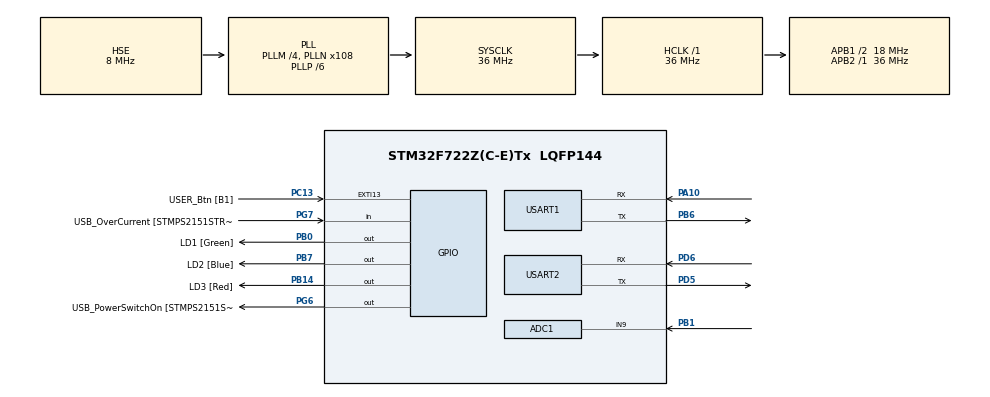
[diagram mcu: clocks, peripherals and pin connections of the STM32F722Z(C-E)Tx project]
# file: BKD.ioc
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ADC1.Channel-0\#ChannelRegularConversion=ADC_CHANNEL_9
ADC1.ClockPrescaler=ADC_CLOCK_SYNC_PCLK_DIV8
ADC1.ContinuousConvMode=ENABLE
ADC1.DMAContinuousRequests=ENABLE
ADC1.NbrOfConversionFlag=1
ADC1.Rank-0\#ChannelRegularConversion=1
ADC1.SamplingTime-0\#ChannelRegularConversion=ADC_SAMPLETIME_480CYCLES
ADC1.master=1
Dma.ADC1.0.Direction=DMA_PERIPH_TO_MEMORY
Dma.ADC1.0.FIFOMode=DMA_FIFOMODE_DISABLE
Dma.ADC1.0.Instance=DMA2_Stream0
Dma.ADC1.0.MemDataAlignment=DMA_MDATAALIGN_HALFWORD
Dma.ADC1.0.MemInc=DMA_MINC_ENABLE
Dma.ADC1.0.Mode=DMA_NORMAL
Dma.ADC1.0.PeriphDataAlignment=DMA_PDATAALIGN_HALFWORD
Dma.ADC1.0.PeriphInc=DMA_PINC_DISABLE
Dma.ADC1.0.Priority=DMA_PRIORITY_MEDIUM
Dma.Request0=ADC1
Mcu.Family=STM32F7
Mcu.Name=STM32F722Z(C-E)Tx
Mcu.Package=LQFP144
NVIC.ADC_IRQn=true\:0\:0\:false\:false\:true\:true\:true
NVIC.DMA2_Stream0_IRQn=true\:0\:0\:false\:false\:true\:false\:true
NVIC.PriorityGroup=NVIC_PRIORITYGROUP_4
NVIC.USART1_IRQn=true\:0\:0\:false\:false\:true\:true\:true
NVIC.USART2_IRQn=true\:0\:0\:false\:false\:true\:true\:true
PA10.Mode=Asynchronous
PA10.Signal=USART1_RX
PA13.GPIO_Label=TMS
PA13.Mode=Serial_Wire
PA13.Signal=SYS_JTMS-SWDIO
PA14.GPIO_Label=TCK
PA14.Mode=Serial_Wire
PA14.Signal=SYS_JTCK-SWCLK
PB0.GPIO_Label=LD1 [Green]
PB0.Signal=GPIO_Output
PB1.Signal=ADCx_IN9
PB14.GPIO_Label=LD3 [Red]
PB14.Signal=GPIO_Output
PB3.GPIO_Label=SWO
PB3.Signal=SYS_JTDO-SWO
PB6.Mode=Asynchronous
PB6.Signal=USART1_TX
PB7.GPIO_Label=LD2 [Blue]
PB7.Signal=GPIO_Output
PC13.GPIO_Label=USER_Btn [B1]
PC13.Signal=GPXTI13
PC14-OSC32_IN.Mode=LSE-External-Oscillator
PC14-OSC32_IN.Signal=RCC_OSC32_IN
PC15-OSC32_OUT.Mode=LSE-External-Oscillator
PC15-OSC32_OUT.Signal=RCC_OSC32_OUT
PD5.Mode=Asynchronous
PD5.Signal=USART2_TX
PD6.Mode=Asynchronous
PD6.Signal=USART2_RX
PG6.GPIO_Label=USB_PowerSwitchOn [STMPS2151STR_EN]
PG6.Signal=GPIO_Output
PG7.GPIO_Label=USB_OverCurrent [STMPS2151STR_FAULT]
PG7.Signal=GPIO_Input
PH0-OSC_IN.GPIO_Label=MCO
PH0-OSC_IN.Mode=HSE-External-Clock-Source
PH0-OSC_IN.Signal=RCC_OSC_IN
PH1-OSC_OUT.Mode=HSE-External-Clock-Source
PH1-OSC_OUT.Signal=RCC_OSC_OUT
ProjectManager.HeapSize=0x200
ProjectManager.StackSize=0x400
ProjectManager.TargetToolchain=STM32CubeIDE
RCC.48MHZClocksFreq_Value=24000000
RCC.AHBFreq_Value=36000000
RCC.APB1CLKDivider=RCC_HCLK_DIV2
RCC.APB1Freq_Value=18000000
RCC.APB1TimFreq_Value=36000000
RCC.APB2Freq_Value=36000000
RCC.APB2TimFreq_Value=36000000
RCC.CortexFreq_Value=36000000
RCC.HCLKFreq_Value=36000000
RCC.HSE_VALUE=8000000
RCC.HSI_VALUE=16000000
RCC.PLLM=4
RCC.PLLMUL=RCC_PLL_MUL9
RCC.PLLN=108
RCC.PLLP=RCC_PLLP_DIV6
RCC.PLLQ=4
RCC.PLLSourceVirtual=RCC_PLLSOURCE_HSE
RCC.PRESCALERUSB=RCC_USBCLKSOURCE_PLL_DIV1_5
RCC.SYSCLKFreq_VALUE=36000000
RCC.SYSCLKSource=RCC_SYSCLKSOURCE_PLLCLK
RCC.SYSCLKSourceVirtual=RCC_SYSCLKSOURCE_PLLCLK
RCC.USBFreq_Value=54000000
RCC.VCOOutputFreq_Value=216000000
SH.ADCx_IN9.0=ADC1_IN9,IN9
USART1.VirtualMode-Asynchronous=VM_ASYNC
USART2.VirtualMode-Asynchronous=VM_ASYNC
board=NUCLEO-F722ZE

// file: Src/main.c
/* USER CODE BEGIN Header */
/**
  ******************************************************************************
  * @file           : main.c
  * @brief          : Main program body
  ******************************************************************************
  * @attention
  *
  * <h2><center>&copy; Copyright (c) 2020 STMicroelectronics.
  * All rights reserved.</center></h2>
  *
  * This software component is licensed by ST under Ultimate Liberty license
  * SLA0044, the "License"; You may not use this file except in compliance with
  * the License. You may obtain a copy of the License at:
  *                             www.st.com/SLA0044
  *
  ******************************************************************************
  */
/* USER CODE END Header */

#include "main.h"

/* USER CODE BEGIN Includes */
#include "main_module.h"

/* USER CODE END Includes */

ADC_HandleTypeDef hadc1;
DMA_HandleTypeDef hdma_adc1;

UART_HandleTypeDef huart1;
UART_HandleTypeDef huart2;

void SystemClock_Config(void);
static void MX_GPIO_Init(void);
static void MX_DMA_Init(void);
static void MX_ADC1_Init(void);
static void MX_USART2_UART_Init(void);
static void MX_USART1_UART_Init(void);

int main(void)
{
  /* USER CODE BEGIN 1 */

	//uint16_t count=0;
  /* USER CODE END 1 */

  /* MCU Configuration--------------------------------------------------------*/

  /* Reset of all peripherals, Initializes the Flash interface and the Systick. */
  HAL_Init();

  /* Configure the system clock */
  SystemClock_Config();

  /* Initialize all configured peripherals */
  MX_GPIO_Init();
  MX_DMA_Init();
  MX_ADC1_Init();
  MX_USART2_UART_Init();
  MX_USART1_UART_Init();
  /* USER CODE BEGIN 2 */
  main_module();

  /* USER CODE END 2 */

  /* Infinite loop */
  while (1)
  {

  }
}

void SystemClock_Config(void)
{
  RCC_OscInitTypeDef RCC_OscInitStruct = {0};
  RCC_ClkInitTypeDef RCC_ClkInitStruct = {0};
  RCC_PeriphCLKInitTypeDef PeriphClkInitStruct = {0};

  /** Configure LSE Drive Capability
  */
  HAL_PWR_EnableBkUpAccess();
  /** Configure the main internal regulator output voltage
  */
  __HAL_RCC_PWR_CLK_ENABLE();
  __HAL_PWR_VOLTAGESCALING_CONFIG(PWR_REGULATOR_VOLTAGE_SCALE3);
  /** Initializes the CPU, AHB and APB busses clocks
  */
  RCC_OscInitStruct.OscillatorType = RCC_OSCILLATORTYPE_HSE;
  RCC_OscInitStruct.HSEState = RCC_HSE_BYPASS;
  RCC_OscInitStruct.PLL.PLLState = RCC_PLL_ON;
  RCC_OscInitStruct.PLL.PLLSource = RCC_PLLSOURCE_HSE;
  RCC_OscInitStruct.PLL.PLLM = 4;
  RCC_OscInitStruct.PLL.PLLN = 108;
  RCC_OscInitStruct.PLL.PLLP = RCC_PLLP_DIV6;
  RCC_OscInitStruct.PLL.PLLQ = 4;
  if (HAL_RCC_OscConfig(&RCC_OscInitStruct) != HAL_OK)
  {
    Error_Handler();
  }
  /** Initializes the CPU, AHB and APB busses clocks
  */
  RCC_ClkInitStruct.ClockType = RCC_CLOCKTYPE_HCLK|RCC_CLOCKTYPE_SYSCLK
                              |RCC_CLOCKTYPE_PCLK1|RCC_CLOCKTYPE_PCLK2;
  RCC_ClkInitStruct.SYSCLKSource = RCC_SYSCLKSOURCE_PLLCLK;
  RCC_ClkInitStruct.AHBCLKDivider = RCC_SYSCLK_DIV1;
  RCC_ClkInitStruct.APB1CLKDivider = RCC_HCLK_DIV2;
  RCC_ClkInitStruct.APB2CLKDivider = RCC_HCLK_DIV1;

  if (HAL_RCC_ClockConfig(&RCC_ClkInitStruct, FLASH_LATENCY_1) != HAL_OK)
  {
    Error_Handler();
  }
  PeriphClkInitStruct.PeriphClockSelection = RCC_PERIPHCLK_USART1|RCC_PERIPHCLK_USART2;
  PeriphClkInitStruct.Usart1ClockSelection = RCC_USART1CLKSOURCE_PCLK2;
  PeriphClkInitStruct.Usart2ClockSelection = RCC_USART2CLKSOURCE_PCLK1;
  if (HAL_RCCEx_PeriphCLKConfig(&PeriphClkInitStruct) != HAL_OK)
  {
    Error_Handler();
  }
}

static void MX_ADC1_Init(void)
{

  ADC_ChannelConfTypeDef sConfig = {0};

  /** Configure the global features of the ADC (Clock, Resolution, Data Alignment and number of conversion)
  */
  hadc1.Instance = ADC1;
  hadc1.Init.ClockPrescaler = ADC_CLOCK_SYNC_PCLK_DIV8;
  hadc1.Init.Resolution = ADC_RESOLUTION_12B;
  hadc1.Init.ScanConvMode = ADC_SCAN_DISABLE;
  hadc1.Init.ContinuousConvMode = ENABLE;
  hadc1.Init.DiscontinuousConvMode = DISABLE;
  hadc1.Init.ExternalTrigConvEdge = ADC_EXTERNALTRIGCONVEDGE_NONE;
  hadc1.Init.ExternalTrigConv = ADC_SOFTWARE_START;
  hadc1.Init.DataAlign = ADC_DATAALIGN_RIGHT;
  hadc1.Init.NbrOfConversion = 1;
  hadc1.Init.DMAContinuousRequests = ENABLE;
  hadc1.Init.EOCSelection = ADC_EOC_SINGLE_CONV;
  if (HAL_ADC_Init(&hadc1) != HAL_OK)
  {
    Error_Handler();
  }
  /** Configure for the selected ADC regular channel its corresponding rank in the sequencer and its sample time.
  */
  sConfig.Channel = ADC_CHANNEL_9;
  sConfig.Rank = ADC_REGULAR_RANK_1;
  sConfig.SamplingTime = ADC_SAMPLETIME_480CYCLES;
  if (HAL_ADC_ConfigChannel(&hadc1, &sConfig) != HAL_OK)
  {
    Error_Handler();
  }

}

static void MX_USART1_UART_Init(void)
{

  huart1.Instance = USART1;
  huart1.Init.BaudRate = 115200;
  huart1.Init.WordLength = UART_WORDLENGTH_8B;
  huart1.Init.StopBits = UART_STOPBITS_1;
  huart1.Init.Parity = UART_PARITY_NONE;
  huart1.Init.Mode = UART_MODE_TX_RX;
  huart1.Init.HwFlowCtl = UART_HWCONTROL_NONE;
  huart1.Init.OverSampling = UART_OVERSAMPLING_16;
  huart1.Init.OneBitSampling = UART_ONE_BIT_SAMPLE_DISABLE;
  huart1.AdvancedInit.AdvFeatureInit = UART_ADVFEATURE_NO_INIT;
  if (HAL_UART_Init(&huart1) != HAL_OK)
  {
    Error_Handler();
  }

}

static void MX_USART2_UART_Init(void)
{

  huart2.Instance = USART2;
  huart2.Init.BaudRate = 115200;
  huart2.Init.WordLength = UART_WORDLENGTH_8B;
  huart2.Init.StopBits = UART_STOPBITS_1;
  huart2.Init.Parity = UART_PARITY_NONE;
  huart2.Init.Mode = UART_MODE_TX_RX;
  huart2.Init.HwFlowCtl = UART_HWCONTROL_NONE;
  huart2.Init.OverSampling = UART_OVERSAMPLING_16;
  huart2.Init.OneBitSampling = UART_ONE_BIT_SAMPLE_DISABLE;
  huart2.AdvancedInit.AdvFeatureInit = UART_ADVFEATURE_NO_INIT;
  if (HAL_UART_Init(&huart2) != HAL_OK)
  {
    Error_Handler();
  }

}

static void MX_DMA_Init(void)
{

  /* DMA controller clock enable */
  __HAL_RCC_DMA2_CLK_ENABLE();

  /* DMA interrupt init */
  /* DMA2_Stream0_IRQn interrupt configuration */
  HAL_NVIC_SetPriority(DMA2_Stream0_IRQn, 0, 0);
  HAL_NVIC_EnableIRQ(DMA2_Stream0_IRQn);

}

static void MX_GPIO_Init(void)
{
  GPIO_InitTypeDef GPIO_InitStruct = {0};

  /* GPIO Ports Clock Enable */
  __HAL_RCC_GPIOC_CLK_ENABLE();
  __HAL_RCC_GPIOH_CLK_ENABLE();
  __HAL_RCC_GPIOB_CLK_ENABLE();
  __HAL_RCC_GPIOG_CLK_ENABLE();
  __HAL_RCC_GPIOA_CLK_ENABLE();
  __HAL_RCC_GPIOD_CLK_ENABLE();

  /*Configure GPIO pin Output Level */
  HAL_GPIO_WritePin(GPIOB, LD1_Pin|LD3_Pin|LD2_Pin, GPIO_PIN_RESET);

  /*Configure GPIO pin Output Level */
  HAL_GPIO_WritePin(USB_PowerSwitchOn_GPIO_Port, USB_PowerSwitchOn_Pin, GPIO_PIN_RESET);

  /*Configure GPIO pin : USER_Btn_Pin */
  GPIO_InitStruct.Pin = USER_Btn_Pin;
  GPIO_InitStruct.Mode = GPIO_MODE_IT_RISING;
  GPIO_InitStruct.Pull = GPIO_NOPULL;
  HAL_GPIO_Init(USER_Btn_GPIO_Port, &GPIO_InitStruct);

  /*Configure GPIO pins : LD1_Pin LD3_Pin LD2_Pin */
  GPIO_InitStruct.Pin = LD1_Pin|LD3_Pin|LD2_Pin;
  GPIO_InitStruct.Mode = GPIO_MODE_OUTPUT_PP;
  GPIO_InitStruct.Pull = GPIO_NOPULL;
  GPIO_InitStruct.Speed = GPIO_SPEED_FREQ_LOW;
  HAL_GPIO_Init(GPIOB, &GPIO_InitStruct);

  /*Configure GPIO pin : USB_PowerSwitchOn_Pin */
  GPIO_InitStruct.Pin = USB_PowerSwitchOn_Pin;
  GPIO_InitStruct.Mode = GPIO_MODE_OUTPUT_PP;
  GPIO_InitStruct.Pull = GPIO_NOPULL;
  GPIO_InitStruct.Speed = GPIO_SPEED_FREQ_LOW;
  HAL_GPIO_Init(USB_PowerSwitchOn_GPIO_Port, &GPIO_InitStruct);

  /*Configure GPIO pin : USB_OverCurrent_Pin */
  GPIO_InitStruct.Pin = USB_OverCurrent_Pin;
  GPIO_InitStruct.Mode = GPIO_MODE_INPUT;
  GPIO_InitStruct.Pull = GPIO_NOPULL;
  HAL_GPIO_Init(USB_OverCurrent_GPIO_Port, &GPIO_InitStruct);

}

void Error_Handler(void)
{
}

/************************ (C) COPYRIGHT STMicroelectronics *****END OF FILE****/
